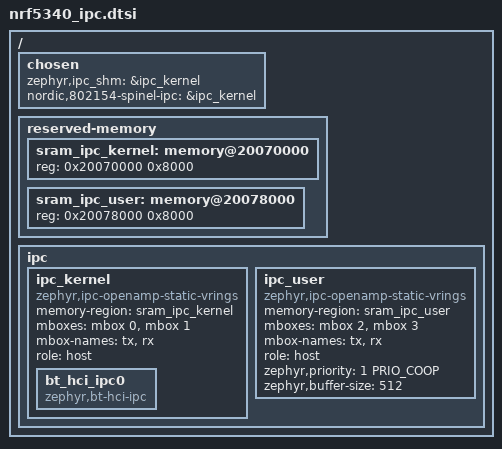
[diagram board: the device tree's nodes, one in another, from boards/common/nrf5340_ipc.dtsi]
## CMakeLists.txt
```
cmake_minimum_required(VERSION 3.30)




# TODO: Still problem; can't include extra .conf files because egg and chicken problem:
# get_cmake_property(_variableNames VARIABLES)
# foreach(_variableName ${_variableNames})
#   message(STATUS "${_variableName} = ${${_variableName}}")
# endforeach()
# message(FATAL_ERROR "DONE")
# if(CONFIG_SOC_SERIES_BSIM_NRFXX)
#   message("Building for BabbleSim; including extra .conf for simulation and analysis")
#   set(EXTRA_CONF_FILES ${EXTRA_CONF_FILES} ${ZEPHYR_SHARED_MODULE_DIR}/soc/bsim_defconfig)
# endif()




find_package(Zephyr REQUIRED HINTS $ENV{ZEPHYR_BASE})

project(gale_sensor_app)

set(CMAKE_EXPORT_COMPILE_COMMANDS ON)

# =============================================================================
set(CMAKE_CXX_STANDARD 20)
set(CMAKE_CXX_STANDARD_REQUIRED ON)

# =============================================================================
target_sources(app PRIVATE
  src/main.cpp
  src/tests/cplusplus.cpp
  src/tests/debugging.cpp
  src/tests/devicetree.cpp
  src/tests/storage.cpp
  src/tests/toys.cpp
  src/tests/emulation.cpp
  src/tests/multicore.cpp
)

target_include_directories(app PRIVATE include)
```

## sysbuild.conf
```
SB_CONFIG_NET_APP_RELAY=y
```

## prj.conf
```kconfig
# =============================================================================
# Peripherals:

CONFIG_GPIO=y
CONFIG_I2C=y

# =============================================================================
# Random toys for playing around with Zephyr features:

CONFIG_CPP_EXCEPTIONS=y
CONFIG_ENTROPY_GENERATOR=y

# Enable binary descriptions, which allow embedding binary data into the application
# in such a way that it is easily readable from the final application binary.
CONFIG_BINDESC=y
CONFIG_BINDESC_DEFINE=y
CONFIG_BINDESC_DEFINE_VERSION=y
CONFIG_BINDESC_DEFINE_BUILD_TIME=y
CONFIG_BINDESC_DEFINE_HOST_INFO=y

CONFIG_BINDESC_APP_BUILD_VERSION=y
CONFIG_BINDESC_BUILD_DATE_TIME_STRING=y
CONFIG_BINDESC_HOST_NAME=y
CONFIG_BINDESC_C_COMPILER_VERSION=y

# =============================================================================
# Drivers:

CONFIG_FUEL_GAUGE=y
```

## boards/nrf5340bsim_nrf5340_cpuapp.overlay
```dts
#include "./common/common.dtsi"
#include "./common/nrf5340_ipc.dtsi"

&flash0 {
	/delete-node/ partitions;
	#include "./common/partitions.dtsi"
};
```

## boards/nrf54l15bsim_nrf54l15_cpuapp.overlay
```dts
#include "./common/common.dtsi"

&cpuapp_rram {
	/delete-node/ partitions;
	#include "./common/partitions.dtsi"
};
```

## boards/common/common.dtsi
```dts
/ {
	#include "./i2c_emul.dtsi"
	#include "./lfs_fstab.dtsi"

	mbox-consumer {
		compatible = "vnd,mbox-consumer";
		mboxes = <&mbox 0>, <&mbox 1>;
		mbox-names = "tx", "rx";
	};
};
```

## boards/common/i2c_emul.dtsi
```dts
/* Defines an emulated I2C controller and an emulated fuel gauge device just for experimentation purposes. */

i2c0: i2c@0 {
	status = "okay";
	compatible = "zephyr,i2c-emul-controller";
	clock-frequency = <I2C_BITRATE_STANDARD>;
	#address-cells = <1>;
	#size-cells = <0>;
	reg = <0x0 4>;
	zephyr,deferred-init;

	/* Simulated device; will talk to projects/zephyr/drivers/fuel_gauge/sbs_gauge/emul_sbs_gauge.c */
	fuel_gauge: fuel_gauge@0 {
		compatible = "sbs,sbs-gauge-new-api";
		status = "okay";
		reg = <0x0>;
		zephyr,deferred-init;
	};
};
```

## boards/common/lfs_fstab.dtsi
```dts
/* Defines a common littlefs filesystem table. */

fstab {
	compatible = "zephyr,fstab";
	lfs1: lfs1 {
		compatible = "zephyr,fstab,littlefs";
		read-size = <16>;
		prog-size = <16>;
		cache-size = <64>;
		lookahead-size = <32>;
		block-cycles = <512>;
		partition = <&storage_partition>;
		mount-point = "/lfs1";
		automount;
	};
};
```

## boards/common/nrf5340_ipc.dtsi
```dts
/* Defines two IPCs 'ipc_kernel' and 'ipc_user' in place of the default 'ipc0'. */

#include <zephyr/dt-bindings/ipc_service/static_vrings.h>

/ {
	chosen {
		zephyr,ipc_shm = &ipc_kernel;
		nordic,802154-spinel-ipc = &ipc_kernel;
	};

	reserved-memory {
		/delete-node/ memory@20070000;

		sram_ipc_kernel: memory@20070000 {
			reg = <0x20070000 0x8000>;
		};

		sram_ipc_user: memory@20078000 {
			reg = <0x20078000 0x8000>;
		};
	};

	ipc {
		/delete-node/ ipc0;

		ipc_kernel: ipc_kernel {
			compatible = "zephyr,ipc-openamp-static-vrings";
			memory-region = <&sram_ipc_kernel>;
			mboxes = <&mbox 0>, <&mbox 1>;
			mbox-names = "tx", "rx";
			role = "host";
			status = "okay";

			bt_hci_ipc0: bt_hci_ipc0 {
				status = "okay";
				compatible = "zephyr,bt-hci-ipc";
			};
		};

		ipc_user: ipc_user {
			compatible = "zephyr,ipc-openamp-static-vrings";
			memory-region = <&sram_ipc_user>;
			mboxes = <&mbox 2>, <&mbox 3>;
			mbox-names = "tx", "rx";
			role = "host";
			zephyr,priority = <1 PRIO_COOP>;
			zephyr,buffer-size = <512>;
			status = "okay";
		};
	};
};
```

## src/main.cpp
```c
#include <app_version.h>
#include <zephyr/kernel.h>

#include "tests/cplusplus.hpp"
#include "tests/devicetree.hpp"
#include "tests/emulation.hpp"
#include "tests/storage.hpp"
#include "tests/toys.hpp"
#include "tests/multicore.hpp"

#include <zephyr/logging/log.h>
LOG_MODULE_REGISTER(main, LOG_LEVEL_DBG);

int main() {
	LOG_INF("Hello, world?! " APP_VERSION_STRING);

	test_storage();
	test_cpp();
	test_devicetree();
	test_toys();
	test_emulation();
	test_multicore();

	int i = 0;
	while (true) {
		LOG_INF("TICK #%d!", i++);
		k_sleep(K_MSEC(10000));
	}
	return 0;
}
```

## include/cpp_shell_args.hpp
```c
/*
 * A QoL wrapper around getopt for parsing shell arguments.
 *
 * Features:
 *  - Uses both getopt and getopt_long to parse command-line arguments;
 *  - Automatically generates a help message from arguments and prints it out when parsing fails;
 *  - Provides automatic conversion for common types;
 *
 * Usage:
 *  - For short arguments use '-fArg' or '-f Arg' (space or no space) or '-f=Arg'
 *  - For long arguments use only '--file=Arg'
 *
 * Issues:
 *  - When running in Linux native_sim, the getopt_long sometimes crashes if used with invalid
 * argument several times in a row - probably due to some internal state issue- however it doesn't
 * support the 'optreset' flag either so we can't do much about if for now. Very nice bug -
 * whatever.
 */

#include <getopt.h>
#include <optional>
#include <string>
#include <vector>
#include <zephyr/shell/shell.h>

struct Arg {
	Arg(const char* name, const char* help, std::optional<std::string> default_value, bool has_arg)
		: long_name(name), help(help), default_value(default_value), short_name(name[0]), has_arg(has_arg) {}

	const char* long_name;					  // Full name of the argument, e.g. "file"
	const char* help;						  // Human-readable description of the argument
	std::optional<std::string> default_value; // Default value for argument; if not given, the argument is required
	const char short_name;					  // Defaults to the first character of the long name, e.g. 'f'
	bool has_arg;							  // True for non-flag arguments, e.g. '-f test.txt'

	std::optional<std::string> value; // Filled out during parsing by user input or falling back to default value
};

struct IntegerArg : public Arg {
	IntegerArg(const char* help, const char* long_name, std::optional<int> def = std::nullopt)
		: Arg(help, long_name, std::nullopt, true) {
		if (def.has_value()) {
			this->default_value = std::to_string(def.value());
		}
		this->value = this->default_value;
	}
	int get() const { return this->value ? std::stoi(*this->value) : 0; }
};

struct FloatArg : public Arg {
	FloatArg(const char* help, const char* long_name, std::optional<float> def = std::nullopt)
		: Arg(help, long_name, std::nullopt, true) {
		if (def.has_value()) {
			this->default_value = std::to_string(def.value());
		}
		this->value = this->default_value;
	}
	float get() const { return this->value ? std::stof(*this->value) : 0.0f; }
};

struct StringArg : public Arg {
	StringArg(const char* help, const char* long_name, std::optional<const char*> def = std::nullopt)
		: Arg(help, long_name, std::nullopt, true) {
		if (def.has_value()) {
			this->default_value = def.value();
		}
		this->value = this->default_value;
	}
	const char* get() const { return this->value ? this->value->c_str() : "NULL"; }
};

struct FlagArg : public Arg {
	FlagArg(const char* help, const char* long_name) : Arg(help, long_name, std::nullopt, false) {
		this->default_value = "false";
		this->value = "false";
	}
	bool get() const { return this->value ? this->value == "true" : false; }
};

struct Args {
	Args(const char* help, std::vector<Arg*> args) : help(help), args(args) {
		short_opts.reserve(args.size() * 2);
		for (const auto& arg : args) {
			short_opts += arg->short_name;
			if (arg->has_arg) {
				short_opts += ':';
			}
		}

		long_opts.reserve(args.size());
		for (const auto& arg : args) {
			long_opts.emplace_back(
				option{
					arg->long_name,
					arg->has_arg ? required_argument : no_argument,
					nullptr,
					arg->short_name,
				});
		}
	}

	void print_help(const shell* sh) {
		shell_print(sh, "---\n%s\nArguments:", this->help);
		for (size_t i = 0; i < this->args.size(); ++i) {
			std::string required_str = this->args[i]->default_value.has_value()
										   ? "optional, default: " + this->args[i]->default_value.value()
										   : "required";
			shell_print(
				sh,
				"\t-%c, --%s: %s (%s)",
				this->args[i]->short_name,
				this->args[i]->long_name,
				this->args[i]->help,
				required_str.c_str());
		}
	}

	// Return true if all required arguments are parsed successfully, false otherwise.
	bool parse_all(const shell* sh, size_t argc, char** argv) {
		optind = 1; // Reset getopt state.

		while (true) {
			const int opt = getopt_long(argc, argv, short_opts.c_str(), long_opts.data(), NULL);
			if (opt == -1) {
				break;
			}

			for (auto& arg : args) {
				if (arg->short_name == opt) {
					if (arg->has_arg) {
						arg->value = optarg;
					} else {
						arg->value = "true";
					}
					break;
				}
			}
		}

		bool args_missing = false;
		for (auto& arg : args) {
			if (!arg->value.has_value()) {
				shell_print(sh, "Missing required argument: %s", arg->long_name);
				args_missing = true;
			}
		}
		if (args_missing) {
			this->print_help(sh);
			return false;
		}

		return true;
	}

	const char* help;
	std::vector<Arg*> args;

	std::string short_opts;
	std::vector<option> long_opts;
};
```
